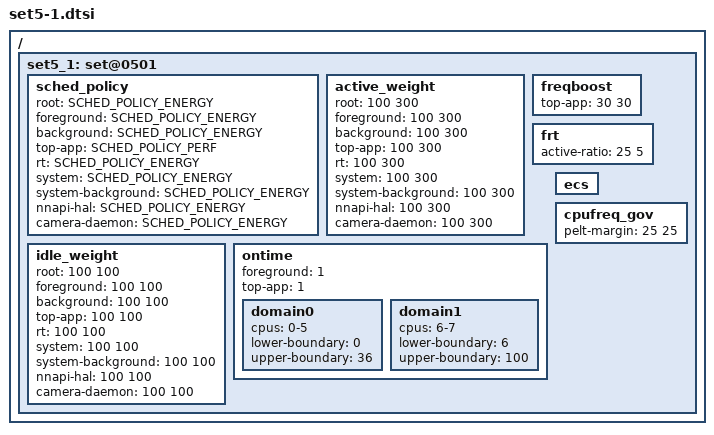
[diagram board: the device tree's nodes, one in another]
/ {
	/* camera mode - touch boost */
	set5_1: set@0501 {
		/* schedudling policy */
		sched_policy {
			root			= <SCHED_POLICY_ENERGY>;
			foreground 		= <SCHED_POLICY_ENERGY>;
			background		= <SCHED_POLICY_ENERGY>;
			top-app			= <SCHED_POLICY_PERF>;
			rt			= <SCHED_POLICY_ENERGY>;
			system			= <SCHED_POLICY_ENERGY>;
			system-background	= <SCHED_POLICY_ENERGY>;
			nnapi-hal		= <SCHED_POLICY_ENERGY>;
			camera-daemon		= <SCHED_POLICY_ENERGY>;
		};

		/* weight (%) applied to active cpu's efficiency */
		active_weight {			/* LIT BIG */
			root			= <100 300>;
			foreground		= <100 300>;
			background		= <100 300>;
			top-app			= <100 300>;
			rt			= <100 300>;
			system			= <100 300>;
			system-background	= <100 300>;
			nnapi-hal		= <100 300>;
			camera-daemon		= <100 300>;
		};

		/* weight (%) applied to idle cpu's efficiency */
		idle_weight {			/* LIT BIG */
			root			= <100 100>;
			foreground		= <100 100>;
			background		= <100 100>;
			top-app			= <100 100>;
			rt			= <100 100>;
			system			= <100 100>;
			system-background	= <100 100>;
			nnapi-hal		= <100 100>;
			camera-daemon		= <100 100>;
		};

		/* Boosting margin applied to frequency selection */
		freqboost {			/* LIT BIG */
			top-app			= < 30 30>;
		};

		frt {				/* LIT BIG */
			active-ratio		= < 25  5>;
		};

		/* Ontime Migration */
		ontime {
			foreground 	= <1>;
			top-app		= <1>;

			domain0 {
				cpus = "0-5";
				lower-boundary = <0>;
				upper-boundary = <36>;
			};
			domain1 {
				cpus = "6-7";
				lower-boundary = <6>;
				upper-boundary = <100>;
			};
		};

		ecs { };

		cpufreq_gov {			/* LIT BIG */
			pelt-margin		= < 25  25>;
		};
	};
};
